# FUSB15200 register map
Vendor: ON Semiconductor; Series: FUSB15200; File version: 1.0
CPU: CM0+ r1p0, little endian, no MPU, no FPU, 3 interrupt priority bits
Registers are 32-bit, read-write, reset 0x0 unless marked. A register's access mark holds for its fields unless they carry their own. Offsets are from the block's base; [hi:lo] are bit positions; {n}, {i} and the like mark numbered series.

## TEST
Base 0x42100000
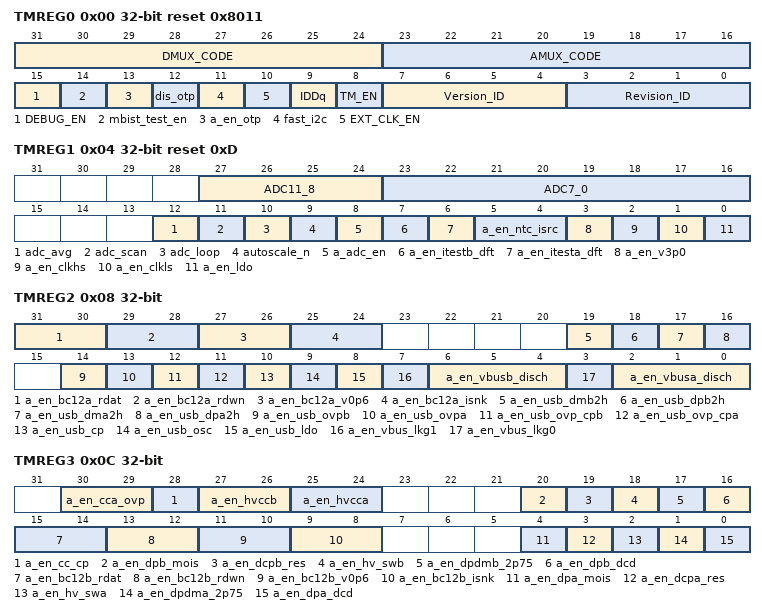
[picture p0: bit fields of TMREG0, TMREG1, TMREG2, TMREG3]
0x00 TMREG0 reset 0x8011 (reset mask 0x101FF11)
  [31:24] DMUX_CODE, [23:16] AMUX_CODE, [15] DEBUG_EN, [14] mbist_test_en, [13] a_en_otp, [12] dis_otp, [11] fast_i2c, [10] EXT_CLK_EN, [9] IDDq, [8] TM_EN, [7:4] Version_ID ro, [3:0] Revision_ID ro
0x04 TMREG1 reset 0xD (reset mask 0x1011FDF)
  [27:24] ADC11_8 ro, [23:16] ADC7_0 ro, [12] adc_avg, [11] adc_scan, [10] adc_loop, [9] autoscale_n, [8] a_adc_en, [7] a_en_itestb_dft, [6] a_en_itesta_dft, [5:4] a_en_ntc_isrc, [3] a_en_v3p0, [2] a_en_clkhs, [1] a_en_clkls, [0] a_en_ldo
0x08 TMREG2 (reset mask 0x550F7F99)
  [31:30] a_en_bc12a_rdat, [29:28] a_en_bc12a_rdwn, [27:26] a_en_bc12a_v0p6, [25:24] a_en_bc12a_isnk, [19] a_en_usb_dmb2h, [18] a_en_usb_dpb2h, [17] a_en_usb_dma2h, [16] a_en_usb_dpa2h, [14] a_en_usb_ovpb, [13] a_en_usb_ovpa, [12] a_en_usb_ovp_cpb, [11] a_en_usb_ovp_cpa, [10] a_en_usb_cp, [9] a_en_usb_osc, [8] a_en_usb_ldo, [7] a_en_vbus_lkg1, [6:4] a_en_vbusb_disch, [3] a_en_vbus_lkg0, [2:0] a_en_vbusa_disch
0x0C TMREG3 (reset mask 0x351F551F)
  [30:29] a_en_cca_ovp, [28] a_en_cc_cp, [27:26] a_en_hvccb, [25:24] a_en_hvcca, [20] a_en_dpb_mois, [19] a_en_dcpb_res, [18] a_en_hv_swb, [17] a_en_dpdmb_2p75, [16] a_en_dpb_dcd, [15:14] a_en_bc12b_rdat, [13:12] a_en_bc12b_rdwn, [11:10] a_en_bc12b_v0p6, [9:8] a_en_bc12b_isnk, [4] a_en_dpa_mois, [3] a_en_dcpa_res, [2] a_en_hv_swa, [1] a_en_dpdma_2p75, [0] a_en_dpa_dcd
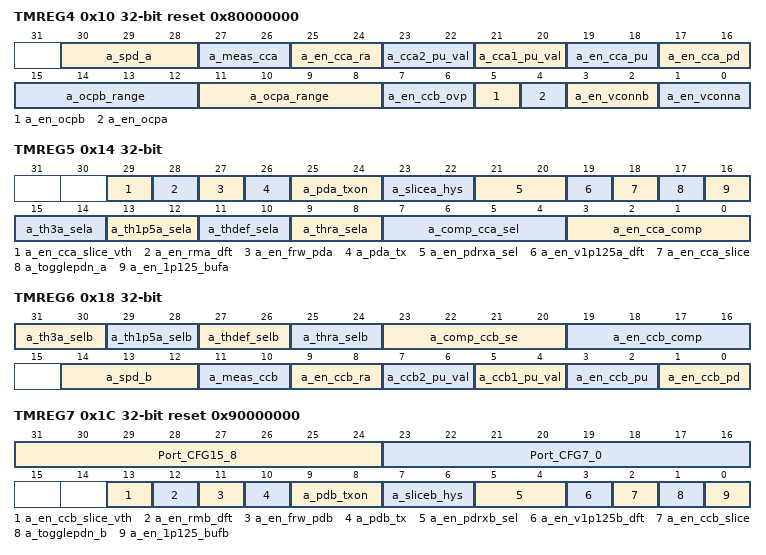
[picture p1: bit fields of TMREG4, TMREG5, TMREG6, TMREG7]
0x10 TMREG4 reset 0x80000000 (reset mask 0x15551175)
  [30:28] a_spd_a, [27:26] a_meas_cca, [25:24] a_en_cca_ra, [23:22] a_cca2_pu_val, [21:20] a_cca1_pu_val, [19:18] a_en_cca_pu, [17:16] a_en_cca_pd, [15:12] a_ocpb_range, [11:8] a_ocpa_range, [7:6] a_en_ccb_ovp, [5] a_en_ocpb, [4] a_en_ocpa, [3:2] a_en_vconnb, [1:0] a_en_vconna
0x14 TMREG5 (reset mask 0x3D5F5511)
  [29] a_en_cca_slice_vth, [28] a_en_rma_dft, [27] a_en_frw_pda, [26] a_pda_tx, [25:24] a_pda_txon, [23:22] a_slicea_hys, [21:20] a_en_pdrxa_sel, [19] a_en_v1p125a_dft, [18] a_en_cca_slice, [17] a_togglepdn_a, [16] a_en_1p125_bufa, [15:14] a_th3a_sela, [13:12] a_th1p5a_sela, [11:10] a_thdef_sela, [9:8] a_thra_sela, [7:4] a_comp_cca_sel, [3:0] a_en_cca_comp
0x18 TMREG6 (reset mask 0x55111555)
  [31:30] a_th3a_selb, [29:28] a_th1p5a_selb, [27:26] a_thdef_selb, [25:24] a_thra_selb, [23:20] a_comp_ccb_se, [19:16] a_en_ccb_comp, [14:12] a_spd_b, [11:10] a_meas_ccb, [9:8] a_en_ccb_ra, [7:6] a_ccb2_pu_val, [5:4] a_ccb1_pu_val, [3:2] a_en_ccb_pu, [1:0] a_en_ccb_pd
0x1C TMREG7 reset 0x90000000 (reset mask 0x1013D5F)
  [31:24] Port_CFG15_8, [23:16] Port_CFG7_0, [13] a_en_ccb_slice_vth, [12] a_en_rmb_dft, [11] a_en_frw_pdb, [10] a_pdb_tx, [9:8] a_pdb_txon, [7:6] a_sliceb_hys, [5:4] a_en_pdrxb_sel, [3] a_en_v1p125b_dft, [2] a_en_ccb_slice, [1] a_togglepdn_b, [0] a_en_1p125_bufb
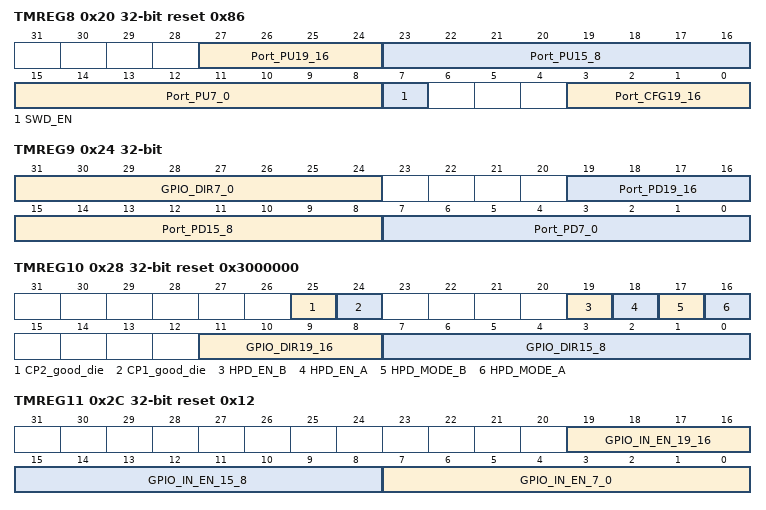
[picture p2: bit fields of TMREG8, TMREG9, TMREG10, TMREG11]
0x20 TMREG8 reset 0x86 (reset mask 0x1010181)
  [27:24] Port_PU19_16, [23:16] Port_PU15_8, [15:8] Port_PU7_0, [7] SWD_EN, [3:0] Port_CFG19_16
0x24 TMREG9 (reset mask 0x1010101)
  [31:24] GPIO_DIR7_0, [19:16] Port_PD19_16, [15:8] Port_PD15_8, [7:0] Port_PD7_0
0x28 TMREG10 reset 0x3000000 (reset mask 0x30F0101)
  [25] CP2_good_die ro, [24] CP1_good_die ro, [19] HPD_EN_B, [18] HPD_EN_A, [17] HPD_MODE_B, [16] HPD_MODE_A, [11:8] GPIO_DIR19_16, [7:0] GPIO_DIR15_8
0x2C TMREG11 reset 0x12 (reset mask 0x10101)
  [19:16] GPIO_IN_EN_19_16, [15:8] GPIO_IN_EN_15_8, [7:0] GPIO_IN_EN_7_0
0x30 TMREG12 (reset mask 0x1)
  [11:0] adc_ch_en
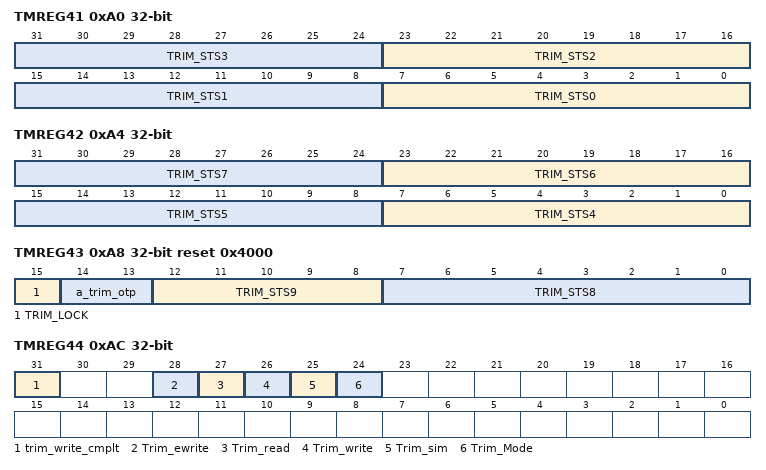
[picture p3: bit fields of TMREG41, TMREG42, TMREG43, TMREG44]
0xA0 TMREG41 (reset mask 0x1010101)
  [8n+7:8n] TRIM_STS{n} ro (n=0..3)
0xA4 TMREG42 (reset mask 0x1010101)
  [8n-25:8n-32] TRIM_STS{n} ro (n=4..7)
0xA8 TMREG43 reset 0x4000 (reset mask 0xA101)
  [15] TRIM_LOCK ro, [14:13] a_trim_otp ro, [12:8] TRIM_STS9 ro, [7:0] TRIM_STS8 ro
0xAC TMREG44
  [31] trim_write_cmplt ro, [28] Trim_ewrite wo, [27] Trim_read, [26] Trim_write wo, [25] Trim_sim, [24] Trim_Mode
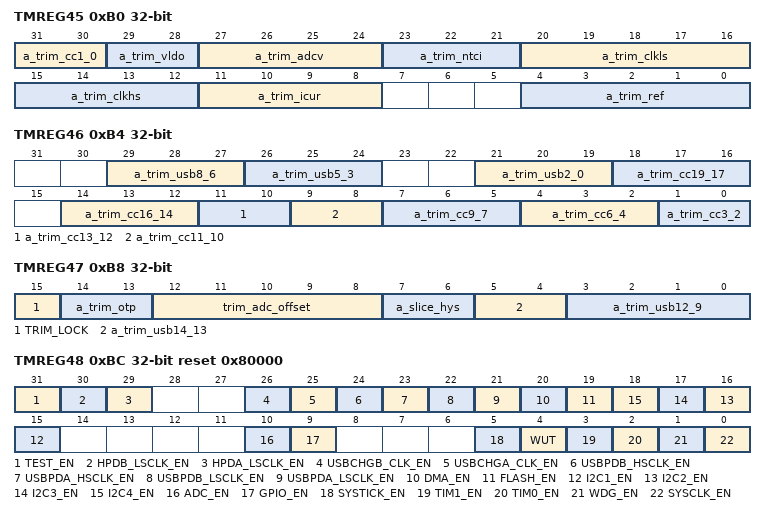
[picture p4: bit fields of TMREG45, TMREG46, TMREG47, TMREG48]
0xB0 TMREG45 (reset mask 0x51211101)
  [31:30] a_trim_cc1_0, [29:28] a_trim_vldo, [27:24] a_trim_adcv, [23:21] a_trim_ntci, [20:16] a_trim_clkls, [15:12] a_trim_clkhs, [11:8] a_trim_icur, [4:0] a_trim_ref
0xB4 TMREG46 (reset mask 0x9091525)
  [29:27] a_trim_usb8_6, [26:24] a_trim_usb5_3, [21:19] a_trim_usb2_0, [18:16] a_trim_cc19_17, [14:12] a_trim_cc16_14, [11:10] a_trim_cc13_12, [9:8] a_trim_cc11_10, [7:5] a_trim_cc9_7, [4:2] a_trim_cc6_4, [1:0] a_trim_cc3_2
0xB8 TMREG47 (reset mask 0xA151)
  [15] TRIM_LOCK, [14:13] a_trim_otp, [12:8] trim_adc_offset, [7:6] a_slice_hys, [5:4] a_trim_usb14_13, [3:0] a_trim_usb12_9
0xBC TMREG48 reset 0x80000
  [31] TEST_EN ro, [30] HPDB_LSCLK_EN ro, [29] HPDA_LSCLK_EN ro, [26] USBCHGB_CLK_EN ro, [25] USBCHGA_CLK_EN ro, [24] USBPDB_HSCLK_EN ro, [23] USBPDA_HSCLK_EN ro, [22] USBPDB_LSCLK_EN ro, [21] USBPDA_LSCLK_EN ro, [20] DMA_EN ro, [19] FLASH_EN ro, [n+14] I2C{n}_EN ro (n=1..4), [10] ADC_EN ro, [9] GPIO_EN ro, [5] SYSTICK_EN ro, [4] WUT ro, [3] TIM1_EN ro, [2] TIM0_EN ro, [1] WDG_EN ro, [0] SYSCLK_EN ro
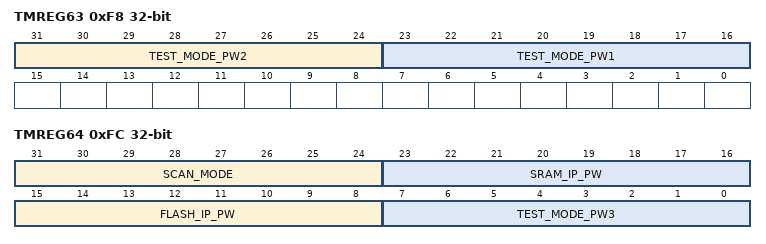
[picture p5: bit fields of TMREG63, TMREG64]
0xF8 TMREG63 (reset mask 0x1010000)
  [31:24] TEST_MODE_PW2 ro, [23:16] TEST_MODE_PW1 ro
0xFC TMREG64 (reset mask 0x1010101)
  [31:24] SCAN_MODE ro, [23:16] SRAM_IP_PW ro, [15:8] FLASH_IP_PW ro, [7:0] TEST_MODE_PW3 ro
